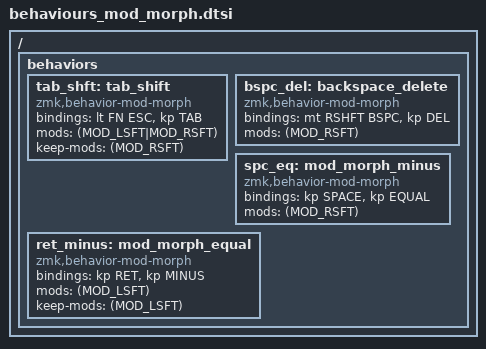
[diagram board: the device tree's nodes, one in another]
/ {
    behaviors {
        tab_shft: tab_shift {
            compatible = "zmk,behavior-mod-morph";
            #binding-cells = <0>;
            bindings = <&lt FN ESC>, <&kp TAB>;
            mods = <(MOD_LSFT|MOD_RSFT)>;
            keep-mods = <(MOD_RSFT)>;
        };
        
        bspc_del: backspace_delete {
            compatible = "zmk,behavior-mod-morph";
            #binding-cells = <0>;
            bindings = <&mt RSHFT BSPC>, <&kp DEL>;
            mods = <(MOD_RSFT)>;
        };

        spc_eq: mod_morph_minus {
            compatible = "zmk,behavior-mod-morph";
            #binding-cells = <0>;
            bindings = <&kp SPACE>, <&kp EQUAL>;
            mods = <(MOD_RSFT)>;
        };

        ret_minus: mod_morph_equal {
            compatible = "zmk,behavior-mod-morph";
            #binding-cells = <0>;
            bindings = <&kp RET>, <&kp MINUS>;
            mods = <(MOD_LSFT)>;
            keep-mods = <(MOD_LSFT)>;
        };
    };
    
};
